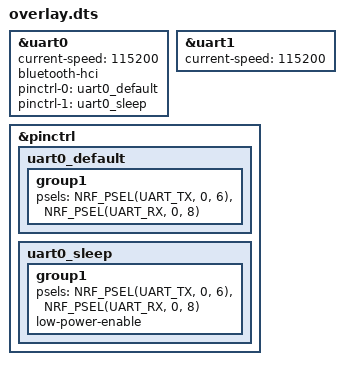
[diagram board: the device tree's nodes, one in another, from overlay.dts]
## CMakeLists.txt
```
cmake_minimum_required(VERSION 3.20.0)
set(BOARD an7002q_db5340)

find_package(Zephyr REQUIRED HINTS $ENV{ZEPHYR_BASE})
project(my_combo_wifi_ble_project)
target_sources(app PRIVATE src/main.c)
```

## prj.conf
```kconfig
# BLE HCI UART (Low Power)
CONFIG_BT=y
CONFIG_BT_HCI_RAW=y
CONFIG_BT_CTLR=y

# Wi-Fi Station
CONFIG_WIFI=y
CONFIG_NET_L2_WIFI_MGMT=y
CONFIG_WIFI_CREDENTIALS=y
CONFIG_NET_SHELL=y

# Zephyr Shell
CONFIG_SHELL=y
CONFIG_UART_CONSOLE=y
CONFIG_CONSOLE=y
CONFIG_PRINTK=y
CONFIG_LOG=y

# Networking
CONFIG_NETWORKING=y
CONFIG_NET_IPV4=y
CONFIG_NET_SOCKETS=y
CONFIG_NET_LOG=y

# Optional: enable assert and serial
CONFIG_ASSERT=y
CONFIG_SERIAL=y


# WiFi credentials backend
CONFIG_WIFI_CREDENTIALS_BACKEND_SETTINGS=y
CONFIG_SETTINGS=y
CONFIG_FLASH=y
CONFIG_FLASH_MAP=y
CONFIG_NVS=y
CONFIG_SETTINGS_NVS=y
```

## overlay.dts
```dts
&uart0 {
    status = "okay";
    current-speed = <115200>;
    bluetooth-hci;
    pinctrl-0 = <&uart0_default>;
    pinctrl-1 = <&uart0_sleep>;
    pinctrl-names = "default", "sleep";
};

&uart1 {
    status = "okay";
    current-speed = <115200>;
};

&pinctrl {
    uart0_default: uart0_default {
        group1 {
            psels = <NRF_PSEL(UART_TX, 0, 6)>,
                    <NRF_PSEL(UART_RX, 0, 8)>;
        };
    };

    uart0_sleep: uart0_sleep {
        group1 {
            psels = <NRF_PSEL(UART_TX, 0, 6)>,
                    <NRF_PSEL(UART_RX, 0, 8)>;
            low-power-enable;
        };
    };
};
```

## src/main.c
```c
#include <zephyr/kernel.h>

int main(void)
{
    printk("BLE HCI + Wi-Fi Shell Firmware Ready\n");
    return 0;
}
```
